# pse84_a0 register map
Vendor: Infineon Technologies; Series: PSE84_A0; File version: 1.0
CPU: CM33 r0p1, little endian, MPU, FPU, VTOR, 3 interrupt priority bits
Registers are 32-bit, read-write, reset 0x0 unless marked. A register's access mark holds for its fields unless they carry their own. Offsets are from the block's base; [hi:lo] are bit positions; lines under a group give offsets from that group.

## SDHC0 (part 3 of 3) — SD/eMMC Host Controller
Base 0x44810000
Same registers: SDHC1 0x44820000
0x1000 CORE group — MMIO for Synopsys Mobile Storage Host Controller IP
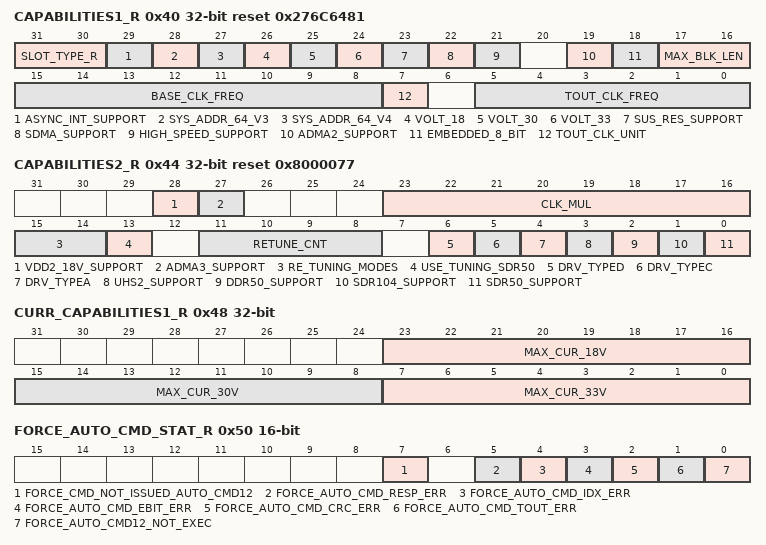
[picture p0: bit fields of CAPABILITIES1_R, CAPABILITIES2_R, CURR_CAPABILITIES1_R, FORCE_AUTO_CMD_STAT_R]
  0x40 CAPABILITIES1_R ro reset 0x276C6481 — Capabilities 1 Register - 0 to 31
    [31:30] SLOT_TYPE_R — Slot Type These bits indicate usage of a slot by a specific Host System. Values: - 0x0 (REMOVABLE_SLOT): Removable Card Slot - 0x1 (EMBEDDED_SLOT): Embedded Slot for one Device - 0x2 (SHARED_SLOT): Shared Bus Slot (SD mode) - 0x3 (UHS2_EMBEDDED_SLOT): UHS-II Multiple Embedded Devices
    [29] ASYNC_INT_SUPPORT — Asynchronous Interrupt Support (SD Mode only) Values: - 0x0 (FALSE): Asynchronous Interrupt Not Supported - 0x1 (TRUE): Asynchronous Interrupt Supported
    [28] SYS_ADDR_64_V3 — 64-bit System Address Support for V3 This bit sets the Host controller to support 64-bit System Addressing of V3 mode. SDMA cannot be used in 64-bit Addressing in Version 3 Mode. If this bit is set to 1, 64-bit ADMA2 with using 96-bit Descriptor can be enabled by setting Host Version 4 Enable (HOST_VER4_ENABLE = 0) and DMA select (DMA_SEL = 11b). Values: - 0x0 (FALSE): 64-bit System Address for V3 is Not Supported - 0x1 (TRUE): 64-bit System Address for V3 is Supported
    [27] SYS_ADDR_64_V4 — 64-bit System Address Support for V4 This bit sets the Host Controller to support 64-bit System Addressing of V4 mode. When this bit is set to 1, full or part of 64-bit address must be used to decode the Host Controller Registers so that Host Controller Registers can be placed above system memory area. 64-bit address decode of Host Controller registers is effective regardless of setting to 64-bit Addressing in Host Control 2. If this bit is set to 1, 64-bit DMA Addressing for version 4 is enabled by setting Host Version 4 Enable (HOST_VER4_ENABLE = 1) and by setting 64-bit Addressing (ADDRESSING =1) in the Host Control 2 register. SDMA can be used and ADMA2 uses 128-bit Descriptor. Values: - 0x0 (FALSE): 64-bit System Address for V4 is Not Supported - 0x1 (TRUE): 64-bit System Address for V4 is Supported
    [26] VOLT_18 — Voltage Support 1.8V Values: - 0x0 (FALSE): 1.8V Not Supported - 0x1 (TRUE): 1.8V Supported
    [25] VOLT_30 — Voltage Support 3.0V Values: - 0x0 (FALSE): 3.0V Not Supported - 0x1 (TRUE): 3.0V Supported
    [24] VOLT_33 — Voltage Support 3.3V Values: - 0x0 (FALSE): 3.3V Not Supported - 0x1 (TRUE): 3.3V Supported
    [23] SUS_RES_SUPPORT — Suspense/Resume Support This bit indicates whether the Host Controller supports Suspend/Resume functionality. If this bit is 0, the Host Driver does not issue either Suspend or Resume commands because the Suspend and Resume mechanism is not supported. Values: - 0x0 (FALSE): Not Supported - 0x1 (TRUE): Supported
    [22] SDMA_SUPPORT — SDMA Support This bit indicates whether the Host Controller is capable of using SDMA to transfer data between the system memory and the Host Controller directly. Values: - 0x0 (FALSE): SDMA not Supported - 0x1 (TRUE): SDMA Supported
    [21] HIGH_SPEED_SUPPORT — High Speed Support This bit indicates whether the Host Controller and the Host System supports High Speed mode and they can supply the SD Clock frequency from 25 MHz to 50 MHz. Values: - 0x0 (FALSE): High Speed not Supported - 0x1 (TRUE): High Speed Supported
    [19] ADMA2_SUPPORT — ADMA2 Support This bit indicates whether the Host Controller is capable of using ADMA2. Values: - 0x0 (FALSE): ADMA2 not Supported - 0x1 (TRUE): ADMA2 Supported
    [18] EMBEDDED_8_BIT — 8-bit Support for Embedded Device This bit indicates whether the Host Controller is capable of using an 8-bit bus width mode. This bit is not effective when the Slot Type is set to 10b. Values: - 0x0 (FALSE): 8-bit Bus Width not Supported - 0x1 (TRUE): 8-bit Bus Width Supported
    [17:16] MAX_BLK_LEN
    [15:8] BASE_CLK_FREQ — Base Clock Frequency for SD clock These bits indicate the base (maximum) clock frequency for the SD Clock. The definition of these bits depend on the Host Controller Version. - 6-Bit Base Clock Frequency: This mode is supported by the Host Controller version 1.00 and 2.00. The upper 2 bits are not effective and are always 0. The unit values are 1 MHz. The supported clock range is 10 MHz to 63 MHz. - 0x00 - Get information through another method - 0x01 - 1 MHz - 0x02 - 2 MHz - ............. - 0x3F - 63 MHz - 0x40-0xFF - Not Supported - 8-Bit Base Clock Frequency: This mode is supported by the Host Controller version 3.00. The unit values are 1 MHz. The supported clock range is 10 MHz to 255 MHz. - 0x00 - Get information through another method - 0x01 - 1 MHz - 0x02 - 2 MHz - ............ - 0xFF - 255 MHz If the frequency is 16.5 MHz, the larger value is set to 0001001b (17 MHz) because the Host Driver uses this value to calculate the clock divider value and it does not exceed the upper limit of the SD Clock frequency. If these bits are all 0, the Host system has to get information using a different method.
    [7] TOUT_CLK_UNIT — Timeout Clock Unit This bit shows the unit of base clock frequency used to detect Data TImeout Error. Values: - 0x0 (KHZ): KHz - 0x1 (MHZ): MHz
    [5:0] TOUT_CLK_FREQ — Timeout Clock Frequency This bit shows the base clock frequency used to detect Data Timeout Error. The Timeout Clock unit defines the unit of timeout clock frequency. It can be KHz or MHz. - 0x00 - Get information through another method - 0x01 - 1KHz / 1MHz - 0x02 - 2KHz / 2MHz - 0x03 - 3KHz / 3MHz - ........... - 0x3F - 63KHz / 63MHz
  0x44 CAPABILITIES2_R ro reset 0x8000077 — Capabilities Register - 32 to 63
    [28] VDD2_18V_SUPPORT — 1.8V VDD2 Support This bit indicates support of VDD2 for the Host System. Values: - 0x0 (FALSE): 1.8V VDD2 is not Supported - 0x1 (TRUE): 1.8V VDD2 is Supported
    [27] ADMA3_SUPPORT — ADMA3 Support This bit indicates whether the Host Controller is capable of using ADMA3. Values: - 0x0 (FALSE): ADMA3 not Supported - 0x1 (TRUE): ADMA3 Supported
    [23:16] CLK_MUL — Clock Multiplier These bits indicate the clock multiplier of the programmable clock generator. Setting these bits to 0 means that the Host Controller does not support a programmable clock generator. - 0x0: Clock Multiplier is not Supported - 0x1: Clock Multiplier M = 2 - 0x2: Clock Multiplier M = 3 - ......... - 0xFF: Clock Multiplier M = 256
    [15:14] RE_TUNING_MODES
    [13] USE_TUNING_SDR50 — Use Tuning for SDR50 (UHS-I only) Values: - 0x0 (ZERO): SDR50 does not require tuning - 0x1 (ONE): SDR50 requires tuning
    [11:8] RETUNE_CNT
    [6] DRV_TYPED — Driver Type D Support (UHS-I only) This bit indicates support of Driver Type D for 1.8 Signaling. Values: - 0x0 (FALSE): Driver Type D is not supported - 0x1 (TRUE): Driver Type D is supported
    [5] DRV_TYPEC — Driver Type C Support (UHS-I only) This bit indicates support of Driver Type C for 1.8 Signaling. Values: - 0x0 (FALSE): Driver Type C is not supported - 0x1 (TRUE): Driver Type C is supported
    [4] DRV_TYPEA — Driver Type A Support (UHS-I only) This bit indicates support of Driver Type A for 1.8 Signaling. Values: - 0x0 (FALSE): Driver Type A is not supported - 0x1 (TRUE): Driver Type A is supported
    [3] UHS2_SUPPORT — UHS-II Support (UHS-II only) This bit indicates whether Host Controller supports UHS-II. Values: - 0x0 (FALSE): UHS-II is not supported - 0x1 (TRUE): UHS-II is supported
    [2] DDR50_SUPPORT — DDR50 Support (UHS-I only) Values: - 0x0 (FALSE): DDR50 is not supported - 0x1 (TRUE): DDR50 is supported
    [1] SDR104_SUPPORT — SDR104 Support (UHS-I only) This bit mentions that SDR104 requires tuning. Values: - 0x0 (FALSE): SDR104 is not supported - 0x1 (TRUE): SDR104 is supported (NOT ACTUALLY SUPPORTED)
    [0] SDR50_SUPPORT — SDR50 Support (UHS-I only) Thsi bit indicates that SDR50 is supported. The bit 13 (USE_TUNING_SDR50) indicates whether SDR50 requires tuning or not. Values: - 0x0 (FALSE): SDR50 is not supported - 0x1 (TRUE): SDR50 is supported
  0x48 CURR_CAPABILITIES1_R ro — Current Capabilities Register - 0 to 31
    [23:16] MAX_CUR_18V — Maximum Current for 1.8V This bit specifies the Maximum Current for 1.8V VDD1 power supply for the card. - 0: Get information through another method - 1: 4mA - 2: 8mA - 3: 13mA - ....... - 255: 1020mA
    [15:8] MAX_CUR_30V — Maximum Current for 3.0V This bit specifies the Maximum Current for 3.0V VDD1 power supply for the card. - 0: Get information through another method - 1: 4mA - 2: 8mA - 3: 13mA - ....... - 255: 1020mA
    [7:0] MAX_CUR_33V — Maximum Current for 3.3V This bit specifies the Maximum Current for 3.3V VDD1 power supply for the card. - 0: Get information through another method - 1: 4mA - 2: 8mA - 3: 13mA - ....... - 255: 1020mA
  0x4C CURR_CAPABILITIES2_R ro — Maximum Current Capabilities Register - 32 to 63
    [7:0] MAX_CUR_VDD2_18V — Maximum Current for 1.8V VDD2 This bit specifies the Maximum Current for 1.8V VDD2 power supply for the UHS-II card. - 0: Get information through another method - 1: 4mA - 2: 8mA - 3: 13mA - ....... - 255: 1020mA
  0x50 FORCE_AUTO_CMD_STAT_R 16-bit wo — Force Event Register for Auto CMD Error Status register
    [7] FORCE_CMD_NOT_ISSUED_AUTO_CMD12 — Force Event for Command Not Issued By Auto CMD12 Error Values: - 0x1 (TRUE): Command Not Issued By Auto CMD12 Error Status is set - 0x0 (FALSE): Not Affected
    [5] FORCE_AUTO_CMD_RESP_ERR — Force Event for Auto CMD Response Error Values: - 0x1 (TRUE): Auto CMD Response Error Status is set - 0x0 (FALSE): Not Affected
    [4] FORCE_AUTO_CMD_IDX_ERR — Force Event for Auto CMD Index Error Values: - 0x1 (TRUE): Auto CMD Index Error Status is set - 0x0 (FALSE): Not Affected
    [3] FORCE_AUTO_CMD_EBIT_ERR — Force Event for Auto CMD End Bit Error Values: - 0x1 (TRUE): Auto CMD End Bit Error Status is set - 0x0 (FALSE): Not Affected
    [2] FORCE_AUTO_CMD_CRC_ERR — Force Event for Auto CMD CRC Error Values: - 0x1 (TRUE): Auto CMD CRC Error Status is set - 0x0 (FALSE): Not Affected
    [1] FORCE_AUTO_CMD_TOUT_ERR — Force Event for Auto CMD Timeout Error Values: - 0x1 (TRUE): Auto CMD Timeout Error Status is set - 0x0 (FALSE): Not Affected
    [0] FORCE_AUTO_CMD12_NOT_EXEC — Force Event for Auto CMD12 Not Executed Values: - 0x1 (TRUE): Auto CMD12 Not Executed Status is set - 0x0 (FALSE): Not Affected
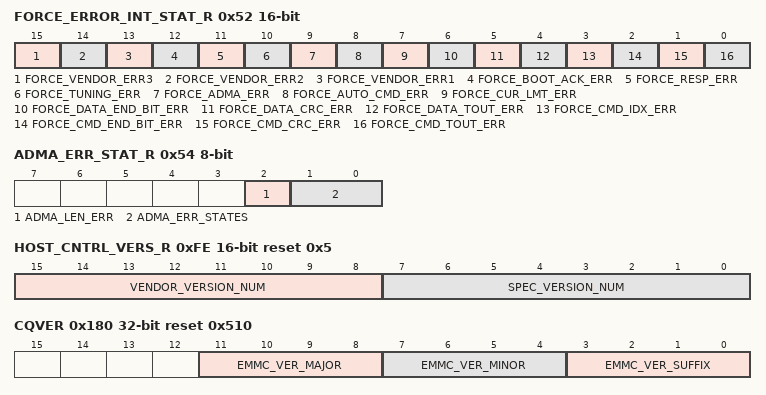
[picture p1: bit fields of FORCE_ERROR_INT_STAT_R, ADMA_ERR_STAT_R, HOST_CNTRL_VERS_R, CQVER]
  0x52 FORCE_ERROR_INT_STAT_R 16-bit — Force Event Register for Error Interrupt Status
    [15] FORCE_VENDOR_ERR3
    [14] FORCE_VENDOR_ERR2
    [13] FORCE_VENDOR_ERR1
    [12] FORCE_BOOT_ACK_ERR — Force Event for Boot Ack error Values: - 0x0 (FALSE): Not Affected - 0x1 (TRUE): Boot ack Error Status is set
    [11] FORCE_RESP_ERR — Force Event for Response Error (SD Mode only) Values: - 0x0 (FALSE): Not Affected - 0x1 (TRUE): Response Error Status is set
    [10] FORCE_TUNING_ERR — Force Event for Tuning Error (UHS-I Mode only) Values: - 0x0 (FALSE): Not Affected - 0x1 (TRUE): Tuning Error Status is set
    [9] FORCE_ADMA_ERR — Force Event for ADMA Error Values: - 0x0 (FALSE): Not Affected - 0x1 (TRUE): ADMA Error Status is set
    [8] FORCE_AUTO_CMD_ERR — Force Event for Auto CMD Error (SD/eMMC Mode only) Values: - 0x0 (FALSE): Not Affected - 0x1 (TRUE): Auto CMD Error Status is set
    [7] FORCE_CUR_LMT_ERR — Force Event for Current Limit Error Values: - 0x0 (FALSE): Not Affected - 0x1 (TRUE): Current Limit Error Status is set
    [6] FORCE_DATA_END_BIT_ERR — Force Event for Data End Bit Error (SD/eMMC Mode only) Values: - 0x0 (FALSE): Not Affected - 0x1 (TRUE): Data End Bit Error Status is set
    [5] FORCE_DATA_CRC_ERR — Force Event for Data CRC Error (SD/eMMC Mode only) Values: - 0x0 (FALSE): Not Affected - 0x1 (TRUE): Data CRC Error Status is set
    [4] FORCE_DATA_TOUT_ERR — Force Event for Data Timeout Error (SD/eMMC Mode only) Values: - 0x0 (FALSE): Not Affected - 0x1 (TRUE): Data Timeout Error Status is set
    [3] FORCE_CMD_IDX_ERR — Force Event for Command Index Error (SD/eMMC Mode only) Values: - 0x0 (FALSE): Not Affected - 0x1 (TRUE): Command Index Error Status is set
    [2] FORCE_CMD_END_BIT_ERR — Force Event for Command End Bit Error (SD/eMMC Mode only) Values: - 0x0 (FALSE): Not Affected - 0x1 (TRUE): Command End Bit Error Status is set
    [1] FORCE_CMD_CRC_ERR — Force Event for Command CRC Error (SD/eMMC Mode only) Values: - 0x0 (FALSE): Not Affected - 0x1 (TRUE): Command CRC Error Status is set
    [0] FORCE_CMD_TOUT_ERR — Force Event for Command Timeout Error (SD/eMMC Mode only) Values: - 0x0 (FALSE): Not Affected - 0x1 (TRUE): Command Timeout Error Status is set
  0x54 ADMA_ERR_STAT_R 8-bit ro — ADMA Error Status Register
    [2] ADMA_LEN_ERR — ADMA Length Mismatch Error States This error occurs in the following instances: - While the Block Count Enable is being set, the total data length specified by the Descriptor table is different from that specified by the Block Count and Block Length - When the total data length cannot be divided by the block length Values: - 0x0 (NO_ERR): No Error - 0x1 (ERROR): Error
    [1:0] ADMA_ERR_STATES — ADMA Error States These bits indicate the state of ADMA when an error occurs during ADMA data transfer. Values: - 0x0 (ST_STOP): Stop DMA - SYS_ADR register points to a location next to the error descriptor - 0x1 (ST_FDS): Fetch Descriptor - SYS_ADR register points to the error descriptor - 0x2 (UNUSED): Never set this state - 0x3 (ST_TFR): Transfer Data - SYS_ADR register points to a location next to the error descriptor
  0x58 ADMA_SA_LOW_R — ADMA System Address Register - Low
    [31:0] ADMA_SA_LOW — ADMA System Address These bits indicate the lower 32 bits of the ADMA system address. - SDMA: If Host Version 4 Enable is set to 1, this register stores the system address of the data location - ADMA2: This register stores the byte address of the executing command of the descriptor table - ADMA3: This register is set by ADMA3. ADMA2 increments the address of this register that points to the next line, every time a Descriptor line is fetched.
  0x78 ADMA_ID_LOW_R — ADMA3 Integrated Descriptor Address Register - Low
    [31:0] ADMA_ID_LOW — ADMA Integrated Descriptor Address These bits indicate the lower 32-bit of the ADMA Integrated Descriptor address. The start address of Integrated Descriptor is set to these register bits. The ADMA3 fetches one Descriptor Address and increments these bits to indicate the next Descriptor address.
  0xFE HOST_CNTRL_VERS_R 16-bit ro reset 0x5 — Host Controller Version
    [15:8] VENDOR_VERSION_NUM, [7:0] SPEC_VERSION_NUM
  0x180 CQVER ro reset 0x510 — Command Queuing Version register
    [11:8] EMMC_VER_MAJOR — This bit indicates the eMMC major version (1st digit left of decimal point) in BCD format.
    [7:4] EMMC_VER_MINOR — This bit indicates the eMMC minor version (1st digit right of decimal point) in BCD format.
    [3:0] EMMC_VER_SUFFIX — This bit indicates the eMMC version suffix (2nd digit right of decimal point) in BCD format.
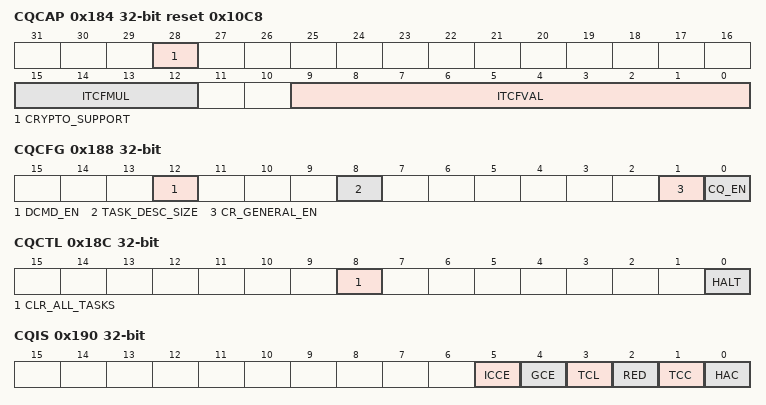
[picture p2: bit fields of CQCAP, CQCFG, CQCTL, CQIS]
  0x184 CQCAP ro reset 0x10C8 — Command Queuing Capabilities register
    [28] CRYPTO_SUPPORT — Crypto Support This bit indicates whether the Host Controller supports cryptographic operations. Values: - 0x0 (FALSE): Crypto not Supported - 0x1 (TRUE): Crypto Supported
    [15:12] ITCFMUL
    [9:0] ITCFVAL — Internal Timer Clock Frequency Value (ITCFVAL) This field scales the frequency of the timer clock provided by ITCFMUL. The Final clock frequency of actual timer clock is calculated as ITCFVAL* ITCFMUL.
  0x188 CQCFG — Command Queuing Configuration register
    [12] DCMD_EN — This bit indicates to the hardware whether the Task Descriptor in slot #31 of the TDL is a data transfer descriptor or a direct-command descriptor. CQE uses this bit when a task is issued in slot #31, to determine how to decode the Task Descriptor. Values: - 0x1 (SLOT31_DCMD_ENABLE): Task descriptor in slot #31 is a DCMD Task Descriptor - 0x0 (SLOT31_DCMD_DISABLE): Task descriptor in slot #31 is a data Transfer Task Descriptor
    [8] TASK_DESC_SIZE — Bit Value Description This bit indicates the size of task descriptor used in host memory. This bit can only be configured when Command Queuing Enable bit is 0 (command queuing is disabled). Values: - 0x1 (TASK_DESC_128b): Task descriptor size is 128 bits - 0x0 (TASK_DESC_64b): Task descriptor size is 64 bits
    [1] CR_GENERAL_EN
    [0] CQ_EN — Enable command queuing engine (CQE). When CQE is disable, the software controls the eMMC bus using the registers between the addresses 0x000 to 0x1FF. Before the software writes to this bit, the software verifies that the eMMC host controller is in idle state and there are no ongoing commands or data transfers. When software wants to exit command queuing mode, it clears all previous tasks (if any) before setting this bit to 0. Values: - 0x1 (CQE_ENABLE): Enable command queuing - 0x0 (CQE_DISABLE): Disable command queuing
  0x18C CQCTL — Command Queuing Control register
    [8] CLR_ALL_TASKS — Clear all tasks This bit can only be written when the controller is halted. This bit does not clear tasks in the device. The software has to use the CMDQ_TASK_MGMT command to clear device's queue. Values: - 0x1 (CLEAR_ALL_TASKS): Clears all the tasks in the controller - 0x0 (NO_EFFECT): Programming 0 has no effect
    [0] HALT — Halt request and resume Values: - 0x1 (HALT_CQE): Software writes 1 to this bit when it wants to acquire software control over the eMMC bus and to disable CQE from issuing command on the bus. For example, issuing a Discard Task command (CMDQ_TASK_MGMT). When the software writes 1, CQE completes the ongoing task (if any in progress). After the task is completed and the CQE is in idle state, CQE does not issue new commands and indicates to the software by setting this bit to 1. The software can poll on this bit until it is set to 1 and only then send commands on the eMMC bus. - 0x0 (RESUME_CQE): Software writes 0 to this bit to exit from the halt state and resume CQE activity.
  0x190 CQIS — Command Queuing Interrupt Status register
    [5] ICCE
    [4] GCE
    [3] TCL — Task cleared interrupt This status bit is asserted (if CQISE.TCL_STE=1) when a task clear operation is completed by CQE. The completed task clear operation is either an individual task clear (by writing CQTCLR) or clearing of all tasks (by writing CQCTL). A value of 1 clears this status bit. Values: - 0x1 (SET): TCL Interrupt is set - 0x0 (NOTSET): TCL Interrupt is not set
    [2] RED — Response error detected interrupt This status bit is asserted (if CQISE.RED_STE=1) when a response is received with an error bit set in the device status field. Configure the CQRMEM register to identify device status bit fields that may trigger an interrupt and that are masked. A value of 1 clears this status bit. Values: - 0x1 (SET): RED Interrupt is set - 0x0 (NOTSET): RED Interrupt is not set
    [1] TCC — Task complete interrupt This status bit is asserted (if CQISE.TCC_STE=1) when at least one of the following conditions are met: - A task is completed and the INT bit is set in its Task Descriptor - Interrupt caused by Interrupt Coalescing logic due to timeout - Interrupt Coalescing logic reached the configured threshold A value of 1 clears this status bit Values: - 0x1 (SET): TCC Interrupt is set - 0x0 (NOTSET): TCC Interrupt is not set
    [0] HAC — Halt complete interrupt This status bit is asserted (only if CQISE.HAC_STE=1) when halt bit in the CQCTL register transitions from 0 to 1 indicating that the host controller has completed its current ongoing task and has entered halt state. A value of 1 clears this status bit. Values: - 0x1 (SET): HAC Interrupt is set - 0x0 (NOTSET): HAC Interrupt is not set
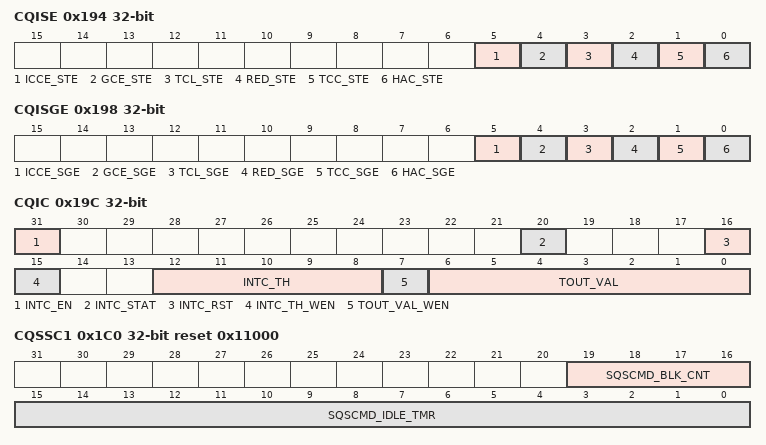
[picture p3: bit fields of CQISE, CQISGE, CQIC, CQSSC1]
  0x194 CQISE — Command Queuing Interrupt Status Enable register
    [5] ICCE_STE — Invalid Crypto Configuration Error interrupt status enable Values: - 0x1 (INT_STS_ENABLE): CQIS.ICCE is set when its interrupt condition is active - 0x0 (INT_STS_DISABLE): CQIS.ICCE is disabled Bit only available if DWC_MSHC_CRYPTO_SUPPORT = 1
    [4] GCE_STE — General Crypto Error interrupt status enable Values: - 0x1 (INT_STS_ENABLE): CQIS.GCE is set when its interrupt condition is active - 0x0 (INT_STS_DISABLE): CQIS.GCE is disabled Bit only available if DWC_MSHC_CRYPTO_SUPPORT = 1
    [3] TCL_STE — Task cleared interrupt status enable Values: - 0x1 (INT_STS_ENABLE): CQIS.TCL is set when its interrupt condition is active - 0x0 (INT_STS_DISABLE): CQIS.TCL is disabled
    [2] RED_STE — Response error detected interrupt status enable Values: - 0x1 (INT_STS_ENABLE): CQIS.RED is set when its interrupt condition is active - 0x0 (INT_STS_DISABLE): CQIS.RED is disabled
    [1] TCC_STE — Task complete interrupt status enable Values: - 0x1 (INT_STS_ENABLE): CQIS.TCC is set when its interrupt condition is active - 0x0 (INT_STS_DISABLE): CQIS.TCC is disabled
    [0] HAC_STE — Halt complete interrupt status enable Values: - 0x1 (INT_STS_ENABLE): CQIS.HAC is set when its interrupt condition is active - 0x0 (INT_STS_DISABLE): CQIS.HAC is disabled
  0x198 CQISGE — Command Queuing Interrupt signal enable register
    [5] ICCE_SGE — Invalid Crypto Configuration Error interrupt signal enable Values: - 0x1 (INT_SIG_ENABLE): CQIS.ICCE interrupt signal generation is active - 0x0 (INT_SIG_DISABLE): CQIS.ICCE interrupt signal generation is disabled Bit only available if DWC_MSHC_CRYPTO_SUPPORT = 1
    [4] GCE_SGE — General Crypto Error interrupt signal enable Values: - 0x1 (INT_SIG_ENABLE): CQIS.GCE interrupt signal generation is active - 0x0 (INT_SIG_DISABLE): CQIS.GCE interrupt signal generation is disabled Bit only available if DWC_MSHC_CRYPTO_SUPPORT = 1
    [3] TCL_SGE — Task cleared interrupt signal enable Values: - 0x1 (INT_SIG_ENABLE): CQIS.TCL interrupt signal generation is active - 0x0 (INT_SIG_DISABLE): CQIS.TCL interrupt signal generation is disabled
    [2] RED_SGE — Response error detected interrupt signal enable Values: - 0x1 (INT_SIG_ENABLE): CQIS.RED interrupt signal generation is active - 0x0 (INT_SIG_DISABLE): CQIS.RED interrupt signal generation is disabled
    [1] TCC_SGE — Task complete interrupt signal enable Values: - 0x1 (INT_SIG_ENABLE): CQIS.TCC interrupt signal generation is active - 0x0 (INT_SIG_DISABLE): CQIS.TCC interrupt signal generation is disabled
    [0] HAC_SGE — Halt complete interrupt signal enable Values: - 0x1 (INT_SIG_ENABLE): CQIS.HAC interrupt signal generation is active - 0x0 (INT_SIG_DISABLE): CQIS.HAC interrupt signal generation is disabled
  0x19C CQIC — Command Queuing Interrupt Coalescing register
    [31] INTC_EN — Interrupt Coalescing Enable Bit Values: - 0x1 (ENABLE_INT_COALESCING): Interrupt coalescing mechanism is active. Interrupts are counted and timed, and coalesced interrupts are generated - 0x0 (DISABLE_INT_COALESCING): Interrupt coalescing mechanism is disabled (Default).
    [20] INTC_STAT ro — Interrupt Coalescing Status Bit This bit indicates to the software whether any tasks (with INT=0) have completed and counted towards interrupt coalescing (that is, this is set if and only if INTC counter > 0). Values: - 0x1 (INTC_ATLEAST1_COMP): At least one INT0 task completion has been counted (INTC counter > 0) - 0x0 (INTC_NO_TASK_COMP): INT0 Task completions have not occurred since last counter reset (INTC counter == 0)
    [16] INTC_RST wo — Counter and Timer Reset When host driver writes 1, the interrupt coalescing timer and counter are reset. Values: - 0x1 (ASSERT_INTC_RESET): Interrupt coalescing timer and counter are reset - 0x0 (NO_EFFECT): No Effect
    [15] INTC_TH_WEN wo — Interrupt Coalescing Counter Threshold Write Enable When software writes 1 to this bit, the value INTC_TH is updated with the contents written on the same cycle. Values: - 0x1 (WEN_SET): Sets INTC_TH_WEN - 0x0 (WEN_CLR): Clears INTC_TH_WEN
    [12:8] INTC_TH wo — Interrupt Coalescing Counter Threshold filed Software uses this field to configure the number of task completions (only tasks with INT=0 in the Task Descriptor), which are required in order to generate an interrupt. Counter Operation: As data transfer tasks with INT=0 complete, they are counted by CQE. The counter is reset by software during the interrupt service routine. The counter stops counting when it reaches the value configured in INTC_TH, and generates interrupt. - 0x0: Interrupt coalescing feature disabled - 0x1: Interrupt coalescing interrupt generated after 1 task when INT=0 completes - 0x2: Interrupt coalescing interrupt generated after 2 tasks when INT=0 completes - ........ - 0x1f: Interrupt coalescing interrupt generated after 31 tasks when INT=0 completes To write to this field, the INTC_TH_WEN bit must be set during the same write operation.
    [7] TOUT_VAL_WEN wo — When software writes 1 to this bit, the value TOUT_VAL is updated with the contents written on the same cycle. Values: - 0x1 (WEN_SET): Sets TOUT_VAL_WEN - 0x0 (WEN_CLR): clears TOUT_VAL_WEN
    [6:0] TOUT_VAL — Interrupt Coalescing Timeout Value Software uses this field to configure the maximum time allowed between the completion of a task on the bus and the generation of an interrupt. Timer Operation: The timer is reset by software during the interrupt service routine. It starts running when the first data transfer task with INT=0 is completed, after the timer was reset. When the timer reaches the value configured in ICTOVAL field, it generates an interrupt and stops. The timer's unit is equal to 1024 clock periods of the clock whose frequency is specified in the Internal Timer Clock Frequency field CQCAP register. - 0x0: Timer is disabled. Timeout-based interrupt is not generated - 0x1: Timeout on 01x1024 cycles of timer clock frequency - 0x2: Timeout on 02x1024 cycles of timer clock frequency - ........ - 0x7f: Timeout on 127x1024 cycles of timer clock frequency In order to write to this field, the TOUT_VAL_WEN bit must be set at the same write operation.
  0x1A0 CQTDLBA — Command Queuing Task Descriptor List Base Address register
    [31:0] TDLBA — This register stores the LSB bits (31:0) of the byte address of the head of the Task Descriptor List in system memory. The size of the task descriptor list is 32 * (Task Descriptor size + Transfer Descriptor size) as configured by the host driver. This address is set on 1 KB boundary. The lower 10 bits of this register are set to 0 by the software and are ignored by CQE.
  0x1A8 CQTDBR — Command Queuing DoorBell register
    [31:0] DBR — The software configures TDLBA and TDLBAU, and enable CQE in CQCFG before using this register. Writing 1 to bit n of this register triggers CQE to start processing the task encoded in slot n of the TDL. Writing 0 by the software does not have any impact on the hardware, and does not change the value of the register bit. CQE always processes tasks according to the order submitted to the list by CQTDBR write transactions. CQE processes Data Transfer tasks by reading the Task Descriptor and sending QUEUED_TASK_PARAMS (CMD44) and QUEUED_TASK_ADDRESS (CMD45) commands to the device. CQE processes DCMD tasks (in slot #31, when enabled) by reading the Task Descriptor, and generating the command encoded by its index and argument. The corresponding bit is cleared to 0 by CQE in one of the following events: - A task execution is completed (with success or error). - The task is cleared using CQTCLR register. - All tasks are cleared using CQCTL register. - CQE is disabled using CQCFG register. Software may initiate multiple tasks at the same time (batch submission) by writing 1 to multiple bits of this register in the same transaction. In the case of batch submission, CQE processes the tasks in order of the task index, starting with the lowest index. If one or more tasks in the batch are marked with QBR, the ordering of execution is based on said processing order.
  0x1AC CQTCN — Command Queuing TaskClear Notification register
    [31:0] TCN — Task Completion Notification Each of the 32 bits are bit mapped to the 32 tasks. - Bit-N(1): Task-N has completed execution (with success or errors) - Bit-N(0): Task-N has not completed, could be pending or not submitted. On task completion, software may read this register to know tasks that have completed. After reading this register, software may clear the relevant bit fields by writing 1 to the corresponding bits.
  0x1B0 CQDQS ro — Device queue status register
    [31:0] DQS — Device Queue Status Each of the 32 bits are bit mapped to the 32 tasks. - Bit-N(1): Device has marked task N as ready for execution - Bit-N(0): Task-N is not ready for execution. This task could be pending in device or not submitted. Host controller updates this register with response of the Device Queue Status command.
  0x1B4 CQDPT ro — Device pending tasks register
    [31:0] DPT — Device-Pending Tasks Each of the 32 bits are bit mapped to the 32 tasks. - Bit-N(1): Task-N has been successfully queued into the device and is awaiting execution - Bit-N(0): Task-N is not yet queued. Bit n of this register is set if and only if QUEUED_TASK_PARAMS (CMD44) and QUEUED_TASK_ADDRESS (CMD45) were sent for this specific task and if this task has not been executed. The controller sets this bit after receiving a successful response for CMD45. CQE clears this bit after the task has completed execution. Software reads this register in the task-discard procedure to determine if the task is queued in the device.
  0x1B8 CQTCLR — Command Queuing DoorBell register
    [31:0] TCLR — Writing 1 to bit n of this register orders CQE to clear a task that the software has previously issued. This bit can only be written when CQE is in Halt state as indicated in CQCFG register Halt bit. When software writes 1 to a bit in this register, CQE updates the value to 1, and starts clearing the data structures related to the task. CQE clears the bit fields (sets a value of 0) in CQTCLR and in CQTDBR once the clear operation is complete. Software must poll on the CQTCLR until it is cleared to verify that a clear operation was done.
  0x1C0 CQSSC1 reset 0x11000 — CQ Send Status Configuration 1 register
    [19:16] SQSCMD_BLK_CNT — This field indicates when SQS CMD is sent while data transfer is in progress. A value of 'n' indicates that CQE sends status command on the CMD line, during the transfer of data block BLOCK_CNTn, on the data lines, where BLOCK_CNT is the number of blocks in the current transaction. - 0x0: SEND_QUEUE_STATUS (CMD13) command is not sent during the transaction. Instead, it is sent only when the data lines are idle. - 0x1: SEND_QUEUE_STATUS command is to be sent during the last block of the transaction. - 0x2: SEND_QUEUE_STATUS command when last 2 blocks are pending. - 0x3: SEND_QUEUE_STATUS command when last 3 blocks are pending. - ........ - 0xf: SEND_QUEUE_STATUS command when last 15 blocks are pending. Should be programmed only when CQCFG.CQ_EN is '0'
    [15:0] SQSCMD_IDLE_TMR — This field configures the polling period to be used when using periodic SEND_QUEUE_STATUS (CMD13) polling. Periodic polling is used when tasks are pending in the device, but no data transfer is in progress. When a SEND_QUEUE_STATUS response indicates that no task is ready for execution, CQE counts the configured time until it issues the next SEND_QUEUE_STATUS. Timer units are clock periods of the clock whose frequency is specified in the Internal Timer Clock Frequency field CQCAP register. The minimum value is 0001h (1 clock period) and the maximum value is FFFFh (65535 clock periods). For example, a CQCAP field value of 0 indicates a 19.2 MHz clock frequency (period = 52.08 ns). If the setting in CQSSC1.CIT is 1000h, the calculated polling period is 4096*52.08 ns= 213.33 ns. Should be programmed only when CQCFG.CQ_EN is '0'.
  0x1C4 CQSSC2 — CQ Send Status Configuration 2 register
    [15:0] SQSCMD_RCA — This field provides CQE with the contents of the 16-bit RCA field in SEND_QUEUE_STATUS (CMD13) command argument. CQE copies this field to bits 31:16 of the argument when transmitting SEND_ QUEUE_STATUS (CMD13) command.
  0x1C8 CQCRDCT ro — Command response for direct command register
    [31:0] DCMD_RESP — This register contains the response of the command generated by the last direct command (DCMD) task that was sent. Contents of this register are valid only after bit 31 of CQTDBR register is cleared by the controller.
  0x1D0 CQRMEM reset 0xFDF9A080 — Command response mode error mask register
    [31:0] RESP_ERR_MASK — The bits of this field are bit mapped to the device response. This bit is used as an interrupt mask on the device status filed that is received in R1/R1b responses. - 1: When a R1/R1b response is received, with a bit i in the device status set, a RED interrupt is generated. - 0: When a R1/R1b response is received, bit i in the device status is ignored. The reset value of this register is set to trigger an interrupt on all 'Error' type bits in the device status. Note: Responses to CMD13 (SQS) encode the QSR so that they are ignored by this logic.
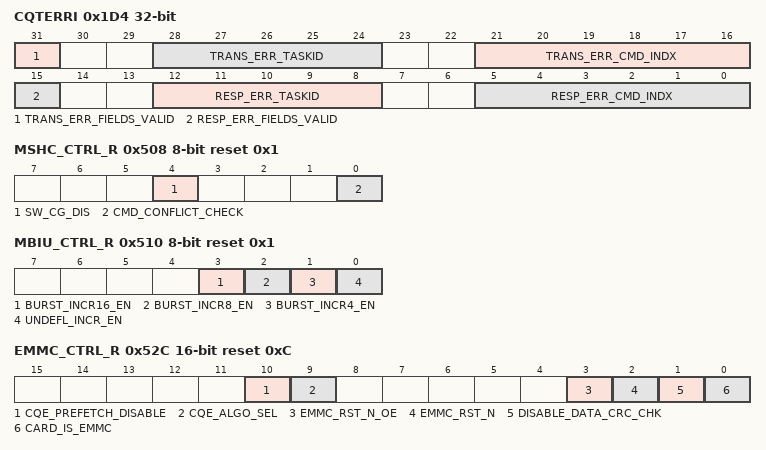
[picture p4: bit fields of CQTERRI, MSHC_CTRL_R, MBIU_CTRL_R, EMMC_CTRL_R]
  0x1D4 CQTERRI ro — CQ Task Error Information register
    [31] TRANS_ERR_FIELDS_VALID — This bit is updated when an error is detected while a data transfer transaction was in progress. Values: - 0x1 (SET): data transfer related error detected. Check contents of TRANS_ERR_TASKID and TRANS_ERR_CMD_INDX fields - 0x0 (NOT_SET): Ignore contents of TRANS_ERR_TASKID and TRANS_ERR_CMD_INDX
    [28:24] TRANS_ERR_TASKID — This field captures the ID of the task that was executed and whose data transfer has errors.
    [21:16] TRANS_ERR_CMD_INDX — This field captures the index of the command that was executed and whose data transfer has errors.
    [15] RESP_ERR_FIELDS_VALID — This bit is updated when an error is detected while a command transaction was in progress. Values: - 0x1 (SET): Response-related error is detected. Check contents of RESP_ERR_TASKID and RESP_ERR_CMD_INDX fields - 0x0 (NOT_SET): Ignore contents of RESP_ERR_TASKID and RESP_ERR_CMD_INDX
    [12:8] RESP_ERR_TASKID — This field captures the ID of the task which was executed on the command line when the error occurred.
    [5:0] RESP_ERR_CMD_INDX — This field captures the index of the command that was executed on the command line when the error occurred.
  0x1D8 CQCRI ro — CQ Command response index
    [5:0] CMD_RESP_INDX — Last Command Response index This field stores the index of the last received command response. Controller updates the value every time a command response is received.
  0x1DC CQCRA ro — CQ Command response argument register
    [31:0] CMD_RESP_ARG — Last Command Response argument This field stores the argument of the last received command response. Controller updates the value every time a command response is received.
  0x500 MSHC_VER_ID_R ro reset 0x3137302A — MSHC version
    [31:0] MSHC_VER_ID — Current release number This field indicates the Synopsys DesignWare Cores DWC_mshc/DWC_mshc_lite current release number that is read by an application. For example, release number '1.60a' is represented in ASCII as 0x313630. Lower 8 bits read from this register can be ignored by the application. An application reading this register in conjunction with the MSHC_VER_TYPE_R register, gathers details of the current release.
  0x504 MSHC_VER_TYPE_R ro reset 0x67612A2A — MSHC version type
    [31:0] MSHC_VER_TYPE — Current release type This field indicates the Synopsys DesignWare Cores DWC_mshc/DWC_mshc_lite current release type that is read by an application. For example, release type is 'ga' is represented in ASCII as 0x6761. Lower 16 bits read from this register can be ignored by the application. An application reading this register in conjunction with the MSHC_VER_ID_R register, gathers details of the current release.
  0x508 MSHC_CTRL_R 8-bit reset 0x1 — MSHC Control register
    [4] SW_CG_DIS — Internal clock gating disable control This bit must be used to disable IP's internal clock gating when required. when disabled clocks are not gated. Clocks to the core (except hclk) must be stopped when programming this bit. Values: - 0x0 (ENABLE): Internal clock gates are active and clock gating is controlled internally - 0x1 (DISABLE): Internal clock gating is disabled, clocks are not gated internally
    [0] CMD_CONFLICT_CHECK — Command conflict check This bit enables command conflict check. Note: DWC_mshc controller monitors the CMD line whenever a command is issued and checks whether the value driven on sd_cmd_out matches the value on sd_cmd_in at next subsequent edge of cclk_tx to determine command conflict error. This bit is cleared only if the feed back delay (including IO Pad delay) is more than (t_card_clk_period - t_setup), where t_setup is the setup time of a flop in DWC_mshc. The I/O pad delay is consistent across CMD and DATA lines, and it is within the value: (2*t_card_clk_period - t_setup) Values: - 0x0 (DISABLE_CMD_CONFLICT_CHK): Disable command conflict check - 0x1 (CMD_CONFLICT_CHK_LAT1): Check for command conflict after 1 card clock cycle
  0x510 MBIU_CTRL_R 8-bit reset 0x1 — MBIU Control register
    [3] BURST_INCR16_EN — INCR16 Burst Controls generation of INCR16 transfers on Master interface. Values: - 0x0 (FALSE): AHB INCR16 burst type is not generated on Master I/F - 0x1 (TRUE): AHB INCR16 burst type can be generated on Master I/F
    [2] BURST_INCR8_EN — INCR8 Burst Controls generation of INCR8 transfers on Master interface. Values: - 0x0 (FALSE): AHB INCR8 burst type is not generated on Master I/F - 0x1 (TRUE): AHB INCR8 burst type can be generated on Master I/F
    [1] BURST_INCR4_EN — INCR4 Burst Controls generation of INCR4 transfers on Master interface. Values: - 0x0 (FALSE): AHB INCR4 burst type is not generated on Master I/F - 0x1 (TRUE): AHB INCR4 burst type can be generated on Master I/F
    [0] UNDEFL_INCR_EN — Undefined INCR Burst Controls generation of undefined length INCR transfer on Master interface. Values: - 0x0 (FALSE): Undefined INCR type burst is the least preferred burst on AHB Master I/F - 0x1 (TRUE): Undefined INCR type burst is the most preferred burst on AHB Master I/F
  0x52C EMMC_CTRL_R 16-bit reset 0xC — eMMC Control register
    [10] CQE_PREFETCH_DISABLE — Enable or Disable CQE's PREFETCH feature This field allows Software to disable CQE's data prefetch feature when set to 1. Values: - 0x0 (PREFETCH_ENABLE): CQE can Prefetch data for sucessive WRITE transfers and pipeline sucessive READ transfers - 0x1 (PREFETCH_DISABLE): Prefetch for WRITE and Pipeline for READ are disabled
    [9] CQE_ALGO_SEL — Scheduler algorithm selected for execution This bit selects the Algorithm used for selecting one of the many ready tasks for execution. Values: - 0x0 (PRI_REORDER_PLUS_FCFS): Priority based reordering with FCFS to resolve equal priority tasks - 0x1 (FCFS_ONLY): First come First serve, in the order of DBR rings
    [3] EMMC_RST_N_OE — Output Enable (OE) control for EMMC Device Reset signal (card_emmc_reset_n). Values: - 0x1 (ENABLE): OE for card_emmc_reset_n is 1 - 0x0 (DISABLE): OE for card_emmc_reset_n is 0
    [2] EMMC_RST_N — EMMC Device Reset signal control. This register field controls the card_emmc_reset_n output of SDHC Values: - 0x1 (RST_DEASSERT): Reset to eMMC device is deasserted - 0x0 (RST_ASSERT): Reset to eMMC device asserted (active low)
    [1] DISABLE_DATA_CRC_CHK — Disable Data CRC Check This bit controls masking of CRC16 error for Card Write in eMMC mode. This is useful in bus testing (CMD19) for an eMMC device. In bus testing, an eMMC card does not send CRC status for a block, which may generate CRC error. This CRC error can be masked using this bit during bus testing. Values: - 0x1 (DISABLE): DATA CRC check is disabled - 0x0 (ENABLE): DATA CRC check is enabled
    [0] CARD_IS_EMMC — eMMC Card present This bit indicates the type of card connected. An application program this bit based on the card connected to SDHC. Values: - 0x1 (EMMC_CARD): Card connected to SDHC is an eMMC card - 0x0 (NON_EMMC_CARD): Card connected to SDHC is a non-eMMC card
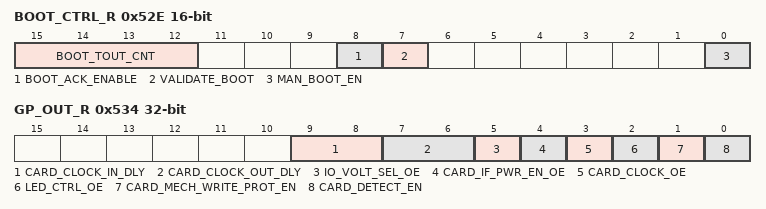
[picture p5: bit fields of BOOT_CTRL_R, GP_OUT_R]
  0x52E BOOT_CTRL_R 16-bit — eMMC Boot Control register
    [15:12] BOOT_TOUT_CNT
    [8] BOOT_ACK_ENABLE — Boot Acknowledge Enable When this bit set, SDHC checks for boot acknowledge start pattern of 0-1-0 during boot operation. This bit is applicable for both mandatory and alternate boot mode. Values: - 0x1 (TRUE): Boot Ack enable - 0x0 (FALSE): Boot Ack disable
    [7] VALIDATE_BOOT wo — Validate Mandatory Boot Enable bit This bit is used to validate the MAN_BOOT_EN bit. Values: - 0x1 (TRUE): Validate Mandatory boot enable bit - 0x0 (FALSE): Ignore Mandatory boot Enable bit
    [0] MAN_BOOT_EN — Mandatory Boot Enable This bit is used to initiate the mandatory boot operation. The application sets this bit along with VALIDATE_BOOT bit. Writing 0 is ignored. The SDHC clears this bit after the boot transfer is completed or terminated. Values: - 0x1 (MAN_BOOT_EN): Mandatory boot enable - 0x0 (MAN_BOOT_DIS): Mandatory boot disable
  0x530 GP_IN_R ro — General Purpose Input register
    [0] GP_IN — It reflects the value of gp_in ports. NOT USED - ALWAYS READS 0
  0x534 GP_OUT_R — General Purpose Output register
    [9:8] CARD_CLOCK_IN_DLY — Delay CARD_CLOCK input internally to optimally sample CMD/DAT; set according to interface mode: 00: SD Default Speed, SD SDR12, eMMC Legacy 01: SD SDR25, SD SDR50 10: SD High Speed, eMMC High Speed SDR 11: SD DDR50, eMMC DDR
    [7:6] CARD_CLOCK_OUT_DLY
    [5] IO_VOLT_SEL_OE — Active high output enable for the IO voltage selection signal (io_volt_sel) controlled through HOST_CTRL_2.SIGNALING_EN: 0: disable OE to the io_volt_sel output 1: enable OE to the io_volt_sel output
    [4] CARD_IF_PWR_EN_OE — Active high output enable for the card interface power enable output (card_if_pwr_en) controlled through PWR_CTRL_R.SD_BUS_PWR_VDD1: 0: disable OE to the card_if_pwr_en output 1: enable OE to the card_if_pwr_en output
    [3] CARD_CLOCK_OE — Active high output enable for the card clock output (clk_card) which is gated by CLK_CTRL_R.SD_CLK_EN: 0: disable OE to the clk_card output 1: enable OE to the clk_card output
    [2] LED_CTRL_OE — Active high output enable for the LED output signal (led_ctrl) controlled through HOST_CTRL1_R.LED_CTRL: 0: disable OE associated with the led_ctrl output 1: enable OE associated with the led_ctrl output
    [1] CARD_MECH_WRITE_PROT_EN — card_mech_write_prot, despite its name, is an active low signal (per the SD Host Controller Standard spec it is officially called SDWP#). Consider that in the following: 0: Force card_mech_write_prot input to 0 internally; this forces write protection to be active 1: Allow card_mech_write_prot to work normally per the device's pin state
    [0] CARD_DETECT_EN — 0: Force card_detect_n input to 0 1: Normal card_detect_n operation allowing card detection from a device pin
